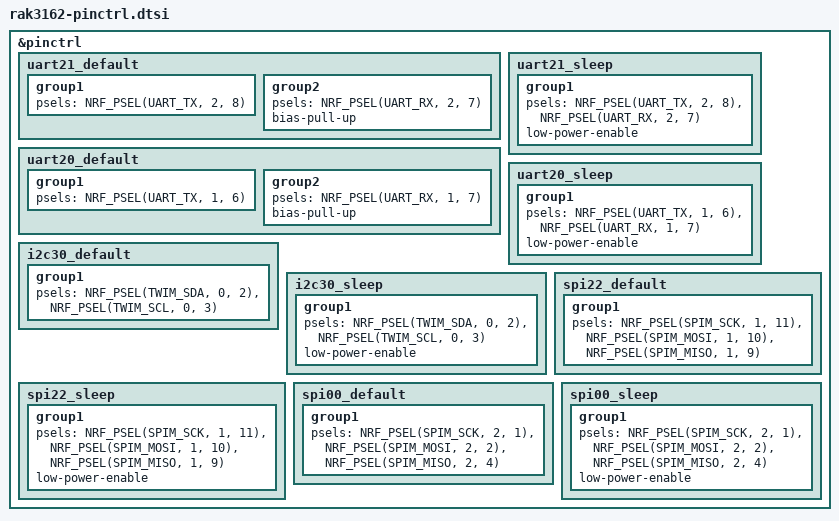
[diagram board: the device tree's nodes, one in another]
/*
 * Copyright (c) 2026 RAKwireless Technology Limited
 * SPDX-License-Identifier: Apache-2.0
 *
 * Pin assignments:
 *   UART0 / uart20 (debug/AT): TX=P1.06, RX=P1.07
 *   UART1 / uart21:            TX=P2.08, RX=P2.07
 *   I2C:             SDA=P0.02, SCL=P0.03
 *   LoRa SPI:        SCK=P1.11, MOSI=P1.10, MISO=P1.09
 *   Ext SPI:         SCK=P2.01, MOSI=P2.02, MISO=P2.04, CS=P2.05 (CS = gpio in rak3162_common.dtsi)
 *
 * LoRa radio GPIO (onboard SX1262):
 *   CS=P1.12, RESET=P0.04, BUSY=P1.13, DIO1=P0.01, ANT_SW=P0.00
 *
 * Optional GRTC 32k measure pin P1.08: see &grtc notes in
 * rak3162_nrf54l15_cpuapp.dts; do not conflict with LoRa bring-up.
 */

&pinctrl {
	/* UART1 / uart21 - Secondary UART: TX=P2.08, RX=P2.07 */
	/omit-if-no-ref/ uart21_default: uart21_default {
		group1 {
			psels = <NRF_PSEL(UART_TX, 2, 8)>;
		};
		group2 {
			psels = <NRF_PSEL(UART_RX, 2, 7)>;
			bias-pull-up;
		};
	};

	/omit-if-no-ref/ uart21_sleep: uart21_sleep {
		group1 {
			psels = <NRF_PSEL(UART_TX, 2, 8)>,
				<NRF_PSEL(UART_RX, 2, 7)>;
			low-power-enable;
		};
	};

	/* UART0 / uart20 - Debug / AT console: TX=P1.06, RX=P1.07 */
	/omit-if-no-ref/ uart20_default: uart20_default {
		group1 {
			psels = <NRF_PSEL(UART_TX, 1, 6)>;
		};
		group2 {
			psels = <NRF_PSEL(UART_RX, 1, 7)>;
			bias-pull-up;
		};
	};

	/omit-if-no-ref/ uart20_sleep: uart20_sleep {
		group1 {
			psels = <NRF_PSEL(UART_TX, 1, 6)>,
				<NRF_PSEL(UART_RX, 1, 7)>;
			low-power-enable;
		};
	};

	/* I2C: SDA=P0.02, SCL=P0.03 */
	/omit-if-no-ref/ i2c30_default: i2c30_default {
		group1 {
			psels = <NRF_PSEL(TWIM_SDA, 0, 2)>,
				<NRF_PSEL(TWIM_SCL, 0, 3)>;
		};
	};

	/omit-if-no-ref/ i2c30_sleep: i2c30_sleep {
		group1 {
			psels = <NRF_PSEL(TWIM_SDA, 0, 2)>,
				<NRF_PSEL(TWIM_SCL, 0, 3)>;
			low-power-enable;
		};
	};

	/* LoRa SPI (spi22): SCK=P1.11, MOSI=P1.10, MISO=P1.09 */
	/omit-if-no-ref/ spi22_default: spi22_default {
		group1 {
			psels = <NRF_PSEL(SPIM_SCK,  1, 11)>,
				<NRF_PSEL(SPIM_MOSI, 1, 10)>,
				<NRF_PSEL(SPIM_MISO, 1,  9)>;
		};
	};

	/omit-if-no-ref/ spi22_sleep: spi22_sleep {
		group1 {
			psels = <NRF_PSEL(SPIM_SCK,  1, 11)>,
				<NRF_PSEL(SPIM_MOSI, 1, 10)>,
				<NRF_PSEL(SPIM_MISO, 1,  9)>;
			low-power-enable;
		};
	};

	/* External/Reserved SPI (spi00): SCK=P2.01, MOSI=P2.02, MISO=P2.04 */
	/omit-if-no-ref/ spi00_default: spi00_default {
		group1 {
			psels = <NRF_PSEL(SPIM_SCK,  2, 1)>,
				<NRF_PSEL(SPIM_MOSI, 2, 2)>,
				<NRF_PSEL(SPIM_MISO, 2, 4)>;
		};
	};

	/omit-if-no-ref/ spi00_sleep: spi00_sleep {
		group1 {
			psels = <NRF_PSEL(SPIM_SCK,  2, 1)>,
				<NRF_PSEL(SPIM_MOSI, 2, 2)>,
				<NRF_PSEL(SPIM_MISO, 2, 4)>;
			low-power-enable;
		};
	};
};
